# GD32VW553x register map
File version: 1.0
CPU: other RISC-V, little endian, no MPU, FPU
Registers are 32-bit, read-write, reset 0x0 unless marked. A register's access mark holds for its fields unless they carry their own. Offsets are from the block's base; [hi:lo] are bit positions.

## TIMER5 — Basic-timers
Base 0x40001000
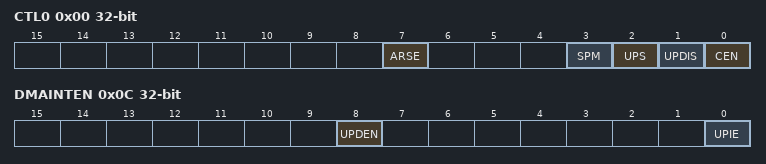
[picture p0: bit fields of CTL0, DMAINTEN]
0x00 CTL0 — control register 0
  [7] ARSE — Auto-reload preload enable
  [3] SPM — One-pulse mode
  [2] UPS — Update request source
  [1] UPDIS — Update disable
  [0] CEN — Counter enable
0x04 CTL1 — control register 1
  [6:4] MMC — Master mode selection
0x0C DMAINTEN — DMA/Interrupt enable register
  [8] UPDEN — Update DMA request enable
  [0] UPIE — Update interrupt enable
0x10 INTF — status register
  [0] UPIF — Update interrupt flag
0x14 SWEVG wo — event generation register
  [0] UPG — Update generation
0x24 CNT — counter
  [15:0] CNT — Low counter value
0x28 PSC — prescaler
  [15:0] PSC — Prescaler value
0x2C CAR — auto-reload register
  [15:0] CARL — Low Auto-reload value

## TRNG — True random number generator
Base 0x4C060800
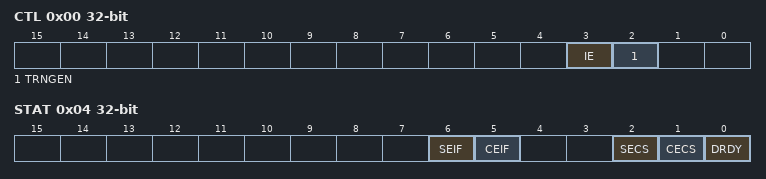
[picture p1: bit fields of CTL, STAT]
0x00 CTL — Control register
  [3] IE — Interrupt enabled bit
  [2] TRNGEN — TRNG enabled bit
0x04 STAT access per field — Status register
  [6] SEIF rw — Seed error interrupt flag
  [5] CEIF rw — Clock error interrupt flag
  [2] SECS ro — Seed error current status
  [1] CECS ro — Clock error current status
  [0] DRDY ro — Random data ready status bit
0x08 DATA ro
  [31:0] TRNDATA — 32-bit random data

## UART1 — Universal asynchronous receiver /transmitter
Base 0x40004400
Same registers: UART2 0x40011000
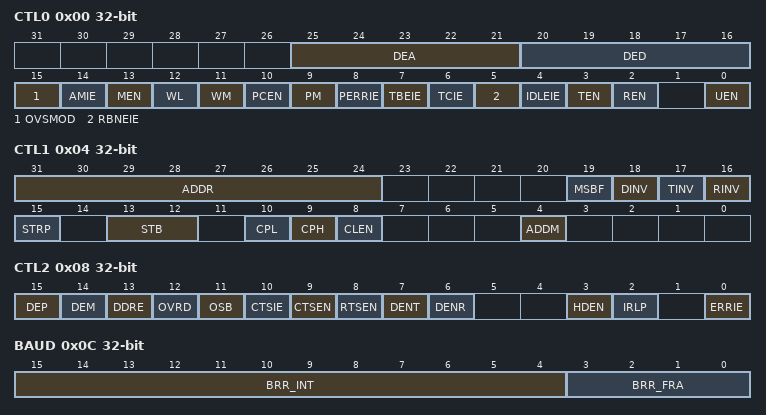
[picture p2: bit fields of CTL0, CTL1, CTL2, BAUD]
0x00 CTL0 — Control register 0
  [25:21] DEA — Driver enable assertion time
  [20:16] DED — Driver enable de-assertion time
  [15] OVSMOD — Oversample mode
  [14] AMIE — ADDR match interrupt enable
  [13] MEN — Mute mode enable
  [12] WL — Word length
  [11] WM — Wakeup method in mute mode
  [10] PCEN — Parity control enable
  [9] PM — Parity mode
  [8] PERRIE — Parity error interrupt enable
  [7] TBEIE — Transmitter register empty interrupt enable
  [6] TCIE — Transmission complete interrupt enable
  [5] RBNEIE — Read data buffer not empty interrupt and overrun error interrupt enable
  [4] IDLEIE — IDLE line detected interrupt enable
  [3] TEN — Transmitter enable
  [2] REN — Receiver enable
  [0] UEN — USART enable
0x04 CTL1 — Control register 1
  [31:24] ADDR — Address of the USART terminal
  [19] MSBF — Most significant bit first
  [18] DINV — Data bit level inversion
  [17] TINV — TX pin level inversion
  [16] RINV — RX pin level inversion
  [15] STRP — Swap TX/RX pins
  [13:12] STB — STOP bits length
  [10] CPL — Clock polarity
  [9] CPH — Clock phase
  [8] CLEN — CK length
  [4] ADDM — Address detection mode
0x08 CTL2 — Control register 2
  [15] DEP — Driver enable polarity mode
  [14] DEM — Driver enable mode
  [13] DDRE — Disable DMA on reception error
  [12] OVRD — Overrun disable
  [11] OSB — One sample bit method
  [10] CTSIE — CTS interrupt enable
  [9] CTSEN — CTS enable
  [8] RTSEN — RTS enable
  [7] DENT — DMA enable for transmission
  [6] DENR — DMA enable for reception
  [3] HDEN — Half-duplex enable
  [2] IRLP — IrDA low-power
  [0] ERRIE — Error interrupt enable
0x0C BAUD — Baud rate generator register
  [15:4] BRR_INT — Integer of baud-rate divider
  [3:0] BRR_FRA — Fraction of baud-rate divider
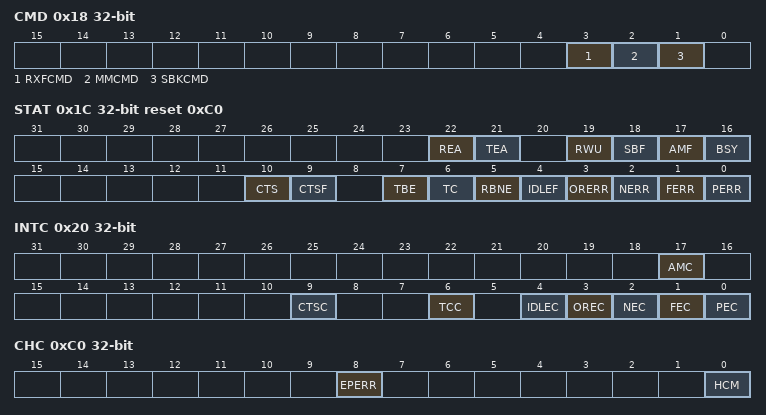
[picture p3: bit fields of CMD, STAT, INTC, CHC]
0x18 CMD wo — Command register
  [3] RXFCMD — Receive data flush command
  [2] MMCMD — Mute mode command
  [1] SBKCMD — Send break command
0x1C STAT ro reset 0xC0 — Status register
  [22] REA — Receive enable acknowledge flag
  [21] TEA — Transmit enable acknowledge flag
  [19] RWU — Receiver wakeup from mute mode
  [18] SBF — Send break flag
  [17] AMF — ADDR match flag
  [16] BSY — Busy flag
  [10] CTS — CTS level
  [9] CTSF — CTS change flag
  [7] TBE — Transmit data register empty
  [6] TC — Transmission completed
  [5] RBNE — Read data buffer not empty
  [4] IDLEF — IDLE line detected flag
  [3] ORERR — Overrun error
  [2] NERR — Noise error flag
  [1] FERR — Frame error flag
  [0] PERR — Parity error flag
0x20 INTC wo — Interrupt status clear register
  [17] AMC — ADDR match clear
  [9] CTSC — CTS change clear
  [6] TCC — Transmission complete clear
  [4] IDLEC — Idle line detected clear
  [3] OREC — Overrun error clear
  [2] NEC — Noise detected clear
  [1] FEC — Frame error flag clear
  [0] PEC — Parity error clear
0x24 RDATA ro — Receive data register
  [8:0] RDATA — Receive data value
0x28 TDATA ro — Transmit data register
  [8:0] TDATA — Transmit data value
0xC0 CHC — USART coherence control register
  [8] EPERR — Early parity error flag
  [0] HCM — Hardware flow control coherence mode
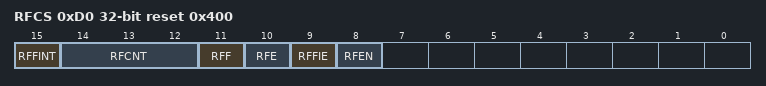
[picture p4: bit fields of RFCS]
0xD0 RFCS access per field reset 0x400 — USART receive FIFO control and status register
  [15] RFFINT rw — Receive FIFO full interrupt flag
  [14:12] RFCNT rw — Receive FIFO counter number
  [11] RFF ro — Receive FIFO full flag
  [10] RFE ro — Receive FIFO empty flag
  [9] RFFIE rw — Receive FIFO full interrupt enable
  [8] RFEN rw — Receive FIFO enable

## WWDGT — Window watchdog timer
Base 0x40002C00
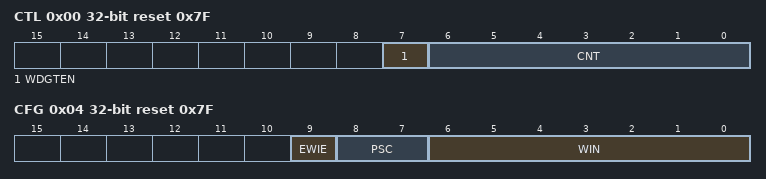
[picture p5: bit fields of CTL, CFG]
0x00 CTL reset 0x7F — Control register
  [7] WDGTEN — Activation bit
  [6:0] CNT — 7-bit counter
0x04 CFG reset 0x7F — Configuration register
  [9] EWIE — Early wakeup interrupt
  [8:7] PSC — Prescaler
  [6:0] WIN — 7-bit window value
0x08 STAT — Status register
  [0] EWIF — Early wakeup interrupt flag
